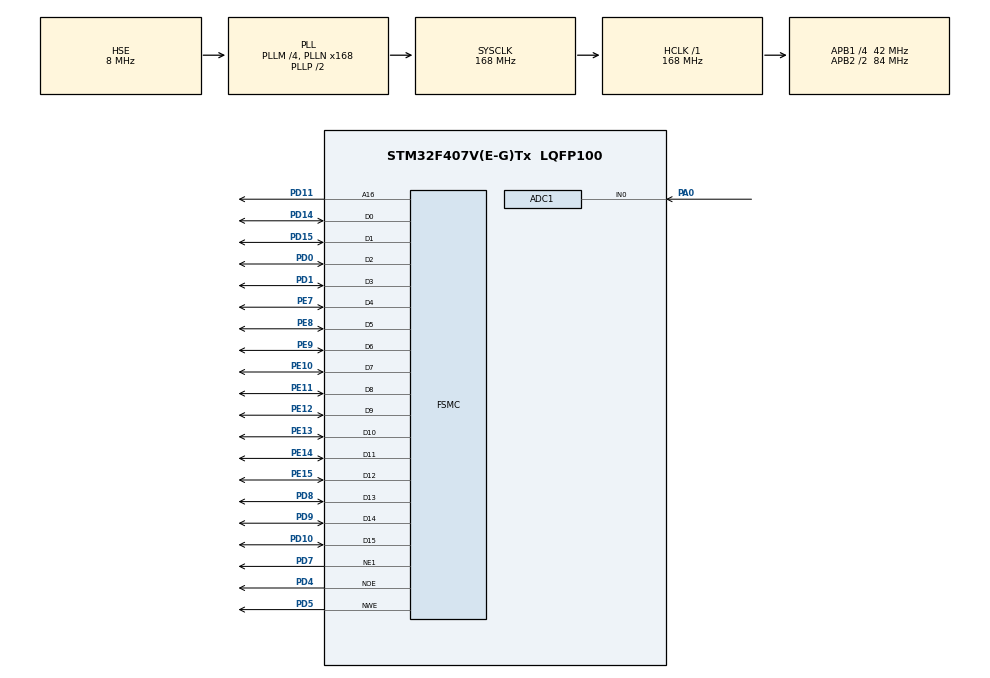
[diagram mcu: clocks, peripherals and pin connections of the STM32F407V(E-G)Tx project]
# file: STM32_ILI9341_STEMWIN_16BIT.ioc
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ADC1.Channel-0\#ChannelRegularConversion=ADC_CHANNEL_0
ADC1.NbrOfConversionFlag=1
ADC1.Rank-0\#ChannelRegularConversion=1
ADC1.SamplingTime-0\#ChannelRegularConversion=ADC_SAMPLETIME_3CYCLES
ADC1.master=1
Mcu.Family=STM32F4
Mcu.Name=STM32F407V(E-G)Tx
Mcu.Package=LQFP100
NVIC.PriorityGroup=NVIC_PRIORITYGROUP_4
PA0-WKUP.Signal=ADCx_IN0
PD0.Mode=16b-d1
PD0.Signal=FSMC_D2
PD1.Mode=16b-d1
PD1.Signal=FSMC_D3
PD10.Mode=16b-d1
PD10.Signal=FSMC_D15
PD11.Mode=A16_1
PD11.Signal=FSMC_A16
PD14.Mode=16b-d1
PD14.Signal=FSMC_D0
PD15.Mode=16b-d1
PD15.Signal=FSMC_D1
PD4.Mode=Lcd1
PD4.Signal=FSMC_NOE
PD5.Mode=Lcd1
PD5.Signal=FSMC_NWE
PD7.Mode=NorPsramChipSelect1_1
PD7.Signal=FSMC_NE1
PD8.Mode=16b-d1
PD8.Signal=FSMC_D13
PD9.Mode=16b-d1
PD9.Signal=FSMC_D14
PE10.Mode=16b-d1
PE10.Signal=FSMC_D7
PE11.Mode=16b-d1
PE11.Signal=FSMC_D8
PE12.Mode=16b-d1
PE12.Signal=FSMC_D9
PE13.Mode=16b-d1
PE13.Signal=FSMC_D10
PE14.Mode=16b-d1
PE14.Signal=FSMC_D11
PE15.Mode=16b-d1
PE15.Signal=FSMC_D12
PE7.Mode=16b-d1
PE7.Signal=FSMC_D4
PE8.Mode=16b-d1
PE8.Signal=FSMC_D5
PE9.Mode=16b-d1
PE9.Signal=FSMC_D6
PH0-OSC_IN.Mode=HSE-External-Oscillator
PH0-OSC_IN.Signal=RCC_OSC_IN
PH1-OSC_OUT.Mode=HSE-External-Oscillator
PH1-OSC_OUT.Signal=RCC_OSC_OUT
ProjectManager.HeapSize=0x200
ProjectManager.StackSize=0x400
ProjectManager.TargetToolchain=STM32CubeIDE
RCC.48MHZClocksFreq_Value=84000000
RCC.AHBFreq_Value=168000000
RCC.APB1CLKDivider=RCC_HCLK_DIV4
RCC.APB1Freq_Value=42000000
RCC.APB1TimFreq_Value=84000000
RCC.APB2CLKDivider=RCC_HCLK_DIV2
RCC.APB2Freq_Value=84000000
RCC.APB2TimFreq_Value=168000000
RCC.CortexFreq_Value=168000000
RCC.HCLKFreq_Value=168000000
RCC.HSE_VALUE=8000000
RCC.HSI_VALUE=16000000
RCC.LSE_VALUE=32768
RCC.PLLM=4
RCC.PLLN=168
RCC.PLLSourceVirtual=RCC_PLLSOURCE_HSE
RCC.SYSCLKFreq_VALUE=168000000
RCC.SYSCLKSource=RCC_SYSCLKSOURCE_PLLCLK
RCC.VCOOutputFreq_Value=336000000
SH.ADCx_IN0.0=ADC1_IN0,IN0
VP_CRC_VS_CRC.Mode=CRC_Activate
board=custom

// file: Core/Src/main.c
/* USER CODE BEGIN Header */
/**
  ******************************************************************************
  * @file           : main.c
  * @brief          : Main program body
  ******************************************************************************
  * @attention
  *
  * <h2><center>&copy; Copyright (c) 2021 STMicroelectronics.
  * All rights reserved.</center></h2>
  *
  * This software component is licensed by ST under BSD 3-Clause license,
  * the "License"; You may not use this file except in compliance with the
  * License. You may obtain a copy of the License at:
  *                        opensource.org/licenses/BSD-3-Clause
  *
  ******************************************************************************
  */
/* USER CODE END Header */
#include "main.h"

/* USER CODE BEGIN Includes */
#include "GUI.h"
/* USER CODE END Includes */

ADC_HandleTypeDef hadc1;

CRC_HandleTypeDef hcrc;

SRAM_HandleTypeDef hsram1;

void SystemClock_Config(void);
static void MX_GPIO_Init(void);
static void MX_ADC1_Init(void);
static void MX_CRC_Init(void);
static void MX_FSMC_Init(void);

int main(void)
{

  /* MCU Configuration--------------------------------------------------------*/

  /* Reset of all peripherals, Initializes the Flash interface and the Systick. */
  HAL_Init();

  /* Configure the system clock */
  SystemClock_Config();

  /* Initialize all configured peripherals */
  MX_GPIO_Init();
  MX_ADC1_Init();
  MX_CRC_Init();
  MX_FSMC_Init();
  /* USER CODE BEGIN 2 */
  GUI_Init();
  MainLCDTask();
  /* USER CODE END 2 */

  /* Infinite loop */
  while (1)
  {

  }
}

void SystemClock_Config(void)
{
  RCC_OscInitTypeDef RCC_OscInitStruct = {0};
  RCC_ClkInitTypeDef RCC_ClkInitStruct = {0};

  /** Configure the main internal regulator output voltage
  */
  __HAL_RCC_PWR_CLK_ENABLE();
  __HAL_PWR_VOLTAGESCALING_CONFIG(PWR_REGULATOR_VOLTAGE_SCALE1);
  /** Initializes the RCC Oscillators according to the specified parameters
  * in the RCC_OscInitTypeDef structure.
  */
  RCC_OscInitStruct.OscillatorType = RCC_OSCILLATORTYPE_HSE;
  RCC_OscInitStruct.HSEState = RCC_HSE_ON;
  RCC_OscInitStruct.PLL.PLLState = RCC_PLL_ON;
  RCC_OscInitStruct.PLL.PLLSource = RCC_PLLSOURCE_HSE;
  RCC_OscInitStruct.PLL.PLLM = 4;
  RCC_OscInitStruct.PLL.PLLN = 168;
  RCC_OscInitStruct.PLL.PLLP = RCC_PLLP_DIV2;
  RCC_OscInitStruct.PLL.PLLQ = 4;
  if (HAL_RCC_OscConfig(&RCC_OscInitStruct) != HAL_OK)
  {
    Error_Handler();
  }
  /** Initializes the CPU, AHB and APB buses clocks
  */
  RCC_ClkInitStruct.ClockType = RCC_CLOCKTYPE_HCLK|RCC_CLOCKTYPE_SYSCLK
                              |RCC_CLOCKTYPE_PCLK1|RCC_CLOCKTYPE_PCLK2;
  RCC_ClkInitStruct.SYSCLKSource = RCC_SYSCLKSOURCE_PLLCLK;
  RCC_ClkInitStruct.AHBCLKDivider = RCC_SYSCLK_DIV1;
  RCC_ClkInitStruct.APB1CLKDivider = RCC_HCLK_DIV4;
  RCC_ClkInitStruct.APB2CLKDivider = RCC_HCLK_DIV2;

  if (HAL_RCC_ClockConfig(&RCC_ClkInitStruct, FLASH_LATENCY_5) != HAL_OK)
  {
    Error_Handler();
  }
}

static void MX_ADC1_Init(void)
{

  ADC_ChannelConfTypeDef sConfig = {0};

  /** Configure the global features of the ADC (Clock, Resolution, Data Alignment and number of conversion)
  */
  hadc1.Instance = ADC1;
  hadc1.Init.ClockPrescaler = ADC_CLOCK_SYNC_PCLK_DIV4;
  hadc1.Init.Resolution = ADC_RESOLUTION_12B;
  hadc1.Init.ScanConvMode = DISABLE;
  hadc1.Init.ContinuousConvMode = DISABLE;
  hadc1.Init.DiscontinuousConvMode = DISABLE;
  hadc1.Init.ExternalTrigConvEdge = ADC_EXTERNALTRIGCONVEDGE_NONE;
  hadc1.Init.ExternalTrigConv = ADC_SOFTWARE_START;
  hadc1.Init.DataAlign = ADC_DATAALIGN_RIGHT;
  hadc1.Init.NbrOfConversion = 1;
  hadc1.Init.DMAContinuousRequests = DISABLE;
  hadc1.Init.EOCSelection = ADC_EOC_SINGLE_CONV;
  if (HAL_ADC_Init(&hadc1) != HAL_OK)
  {
    Error_Handler();
  }
  /** Configure for the selected ADC regular channel its corresponding rank in the sequencer and its sample time.
  */
  sConfig.Channel = ADC_CHANNEL_0;
  sConfig.Rank = 1;
  sConfig.SamplingTime = ADC_SAMPLETIME_3CYCLES;
  if (HAL_ADC_ConfigChannel(&hadc1, &sConfig) != HAL_OK)
  {
    Error_Handler();
  }

}

static void MX_CRC_Init(void)
{

  hcrc.Instance = CRC;
  if (HAL_CRC_Init(&hcrc) != HAL_OK)
  {
    Error_Handler();
  }

}

static void MX_GPIO_Init(void)
{

  /* GPIO Ports Clock Enable */
  __HAL_RCC_GPIOH_CLK_ENABLE();
  __HAL_RCC_GPIOA_CLK_ENABLE();
  __HAL_RCC_GPIOE_CLK_ENABLE();
  __HAL_RCC_GPIOD_CLK_ENABLE();

}

/* FSMC initialization function */
static void MX_FSMC_Init(void)
{

  FSMC_NORSRAM_TimingTypeDef Timing = {0};

  /** Perform the SRAM1 memory initialization sequence
  */
  hsram1.Instance = FSMC_NORSRAM_DEVICE;
  hsram1.Extended = FSMC_NORSRAM_EXTENDED_DEVICE;
  /* hsram1.Init */
  hsram1.Init.NSBank = FSMC_NORSRAM_BANK1;
  hsram1.Init.DataAddressMux = FSMC_DATA_ADDRESS_MUX_DISABLE;
  hsram1.Init.MemoryType = FSMC_MEMORY_TYPE_SRAM;
  hsram1.Init.MemoryDataWidth = FSMC_NORSRAM_MEM_BUS_WIDTH_16;
  hsram1.Init.BurstAccessMode = FSMC_BURST_ACCESS_MODE_DISABLE;
  hsram1.Init.WaitSignalPolarity = FSMC_WAIT_SIGNAL_POLARITY_LOW;
  hsram1.Init.WrapMode = FSMC_WRAP_MODE_DISABLE;
  hsram1.Init.WaitSignalActive = FSMC_WAIT_TIMING_BEFORE_WS;
  hsram1.Init.WriteOperation = FSMC_WRITE_OPERATION_ENABLE;
  hsram1.Init.WaitSignal = FSMC_WAIT_SIGNAL_DISABLE;
  hsram1.Init.ExtendedMode = FSMC_EXTENDED_MODE_DISABLE;
  hsram1.Init.AsynchronousWait = FSMC_ASYNCHRONOUS_WAIT_DISABLE;
  hsram1.Init.WriteBurst = FSMC_WRITE_BURST_DISABLE;
  hsram1.Init.PageSize = FSMC_PAGE_SIZE_NONE;
  /* Timing */
  Timing.AddressSetupTime = 15;
  Timing.AddressHoldTime = 15;
  Timing.DataSetupTime = 255;
  Timing.BusTurnAroundDuration = 15;
  Timing.CLKDivision = 16;
  Timing.DataLatency = 17;
  Timing.AccessMode = FSMC_ACCESS_MODE_A;
  /* ExtTiming */

  if (HAL_SRAM_Init(&hsram1, &Timing, NULL) != HAL_OK)
  {
    Error_Handler( );
  }

}

void Error_Handler(void)
{
  __disable_irq();
  while (1)
  {
  }
}

/************************ (C) COPYRIGHT STMicroelectronics *****END OF FILE****/
